# PIC32MM0256GPM048 register map
Vendor: Microchip
Registers are 32-bit, read-write, reset 0x0 unless marked. A register's access mark holds for its fields unless they carry their own. Addresses are absolute, and some are shared; only a register's first bit layout is shown; [hi:lo] are bit positions; {n}, {i} and the like mark numbered series.

## CLC1
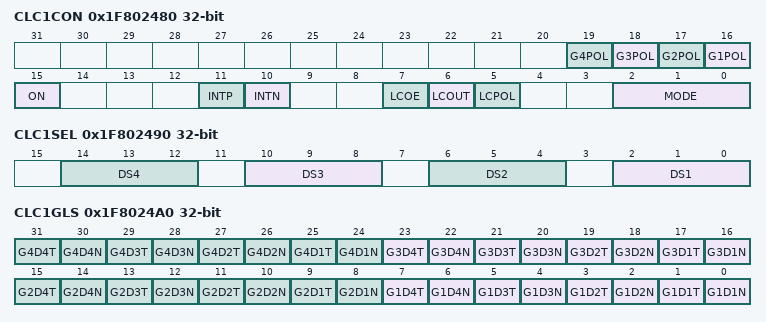
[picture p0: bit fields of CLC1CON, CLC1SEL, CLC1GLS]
0x1F802480 CLC1CON
  [n+15] G{n}POL (n=1..4), [15] ON, [11] INTP, [10] INTN, [7] LCOE, [6] LCOUT, [5] LCPOL, [2:0] MODE
0x1F802490 CLC1SEL
  [4n-2:4n-4] DS{n} (n=1..4)
0x1F8024A0 CLC1GLS
  [8n-1] G{n}D4T (n=1..4), [8n-2] G{n}D4N (n=1..4), [8n-3] G{n}D3T (n=1..4), [8n-4] G{n}D3N (n=1..4), [8n-5] G{n}D2T (n=1..4), [8n-6] G{n}D2N (n=1..4), [8n-7] G{n}D1T (n=1..4), [8n-8] G{n}D1N (n=1..4)

## CLC2
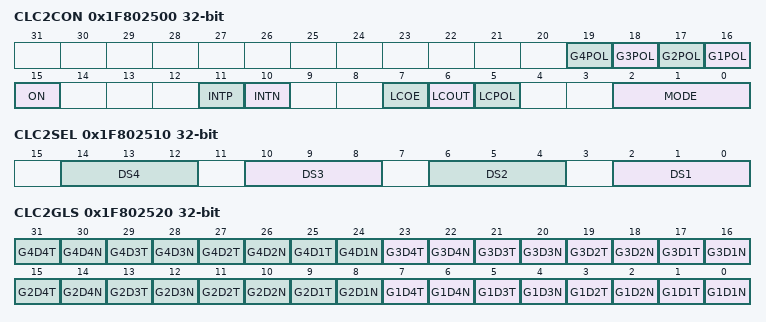
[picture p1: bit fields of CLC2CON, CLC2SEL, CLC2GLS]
0x1F802500 CLC2CON
  [n+15] G{n}POL (n=1..4), [15] ON, [11] INTP, [10] INTN, [7] LCOE, [6] LCOUT, [5] LCPOL, [2:0] MODE
0x1F802510 CLC2SEL
  [4n-2:4n-4] DS{n} (n=1..4)
0x1F802520 CLC2GLS
  [8n-1] G{n}D4T (n=1..4), [8n-2] G{n}D4N (n=1..4), [8n-3] G{n}D3T (n=1..4), [8n-4] G{n}D3N (n=1..4), [8n-5] G{n}D2T (n=1..4), [8n-6] G{n}D2N (n=1..4), [8n-7] G{n}D1T (n=1..4), [8n-8] G{n}D1N (n=1..4)

## CLC3
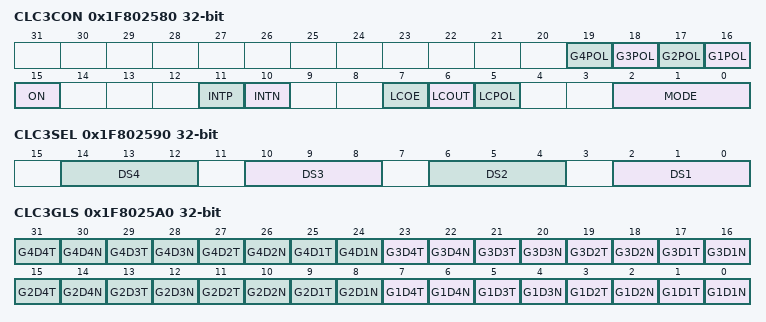
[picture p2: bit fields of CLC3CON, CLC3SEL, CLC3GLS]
0x1F802580 CLC3CON
  [n+15] G{n}POL (n=1..4), [15] ON, [11] INTP, [10] INTN, [7] LCOE, [6] LCOUT, [5] LCPOL, [2:0] MODE
0x1F802590 CLC3SEL
  [4n-2:4n-4] DS{n} (n=1..4)
0x1F8025A0 CLC3GLS
  [8n-1] G{n}D4T (n=1..4), [8n-2] G{n}D4N (n=1..4), [8n-3] G{n}D3T (n=1..4), [8n-4] G{n}D3N (n=1..4), [8n-5] G{n}D2T (n=1..4), [8n-6] G{n}D2N (n=1..4), [8n-7] G{n}D1T (n=1..4), [8n-8] G{n}D1N (n=1..4)

## CLC4
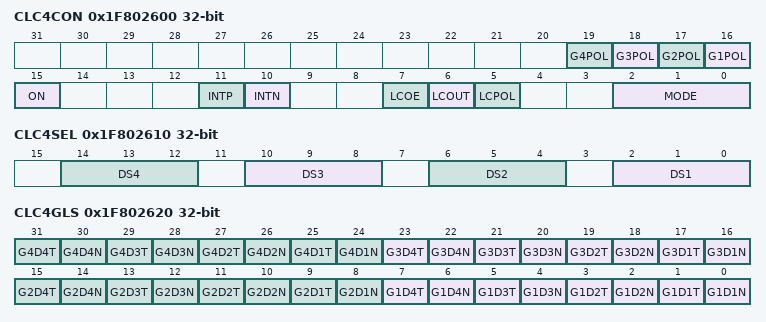
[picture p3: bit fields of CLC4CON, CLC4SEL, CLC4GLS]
0x1F802600 CLC4CON
  [n+15] G{n}POL (n=1..4), [15] ON, [11] INTP, [10] INTN, [7] LCOE, [6] LCOUT, [5] LCPOL, [2:0] MODE
0x1F802610 CLC4SEL
  [4n-2:4n-4] DS{n} (n=1..4)
0x1F802620 CLC4GLS
  [8n-1] G{n}D4T (n=1..4), [8n-2] G{n}D4N (n=1..4), [8n-3] G{n}D3T (n=1..4), [8n-4] G{n}D3N (n=1..4), [8n-5] G{n}D2T (n=1..4), [8n-6] G{n}D2N (n=1..4), [8n-7] G{n}D1T (n=1..4), [8n-8] G{n}D1N (n=1..4)

## CRU
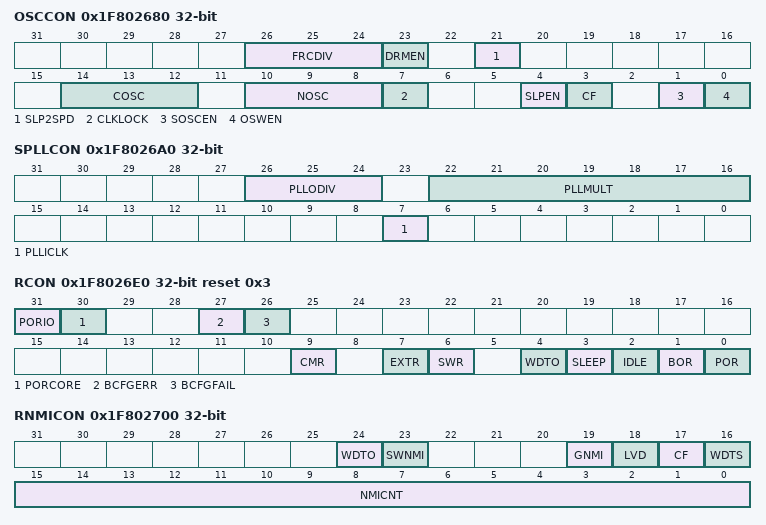
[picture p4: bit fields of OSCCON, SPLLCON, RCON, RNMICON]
0x1F802680 OSCCON reset not defined — (power-on value -----0000-x------000-xxx0--00-x0)
  [26:24] FRCDIV, [23] DRMEN, [21] SLP2SPD, [14:12] COSC ro, [10:8] NOSC, [7] CLKLOCK, [4] SLPEN, [3] CF, [1] SOSCEN, [0] OSWEN
0x1F8026A0 SPLLCON reset not defined — (power-on value -----001-xxxxxxx--------0-------)
  [26:24] PLLODIV, [22:16] PLLMULT, [7] PLLICLK
0x1F8026E0 RCON reset 0x3
  [31] PORIO, [30] PORCORE, [27] BCFGERR, [26] BCFGFAIL, [9] CMR, [7] EXTR, [6] SWR, [4] WDTO, [3] SLEEP, [2] IDLE, [1] BOR, [0] POR
0x1F8026F0 RSWRST wo
  [0] SWRST
0x1F802700 RNMICON reset not defined — (power-on value -------x0---0-000000000000000000)
  [24] WDTO, [23] SWNMI, [19] GNMI, [18] LVD, [17] CF, [16] WDTS, [15:0] NMICNT
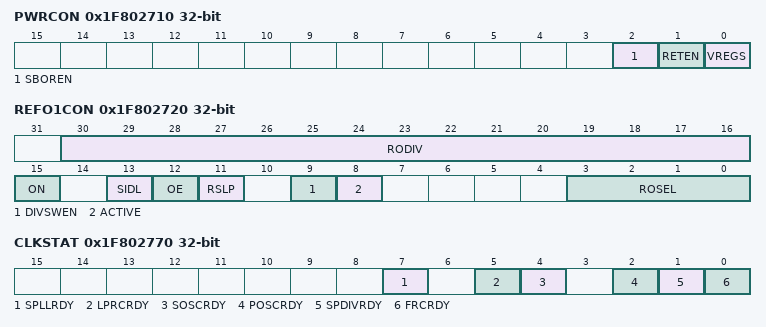
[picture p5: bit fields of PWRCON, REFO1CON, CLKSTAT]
0x1F802710 PWRCON
  [2] SBOREN, [1] RETEN, [0] VREGS
0x1F802720 REFO1CON
  [30:16] RODIV, [15] ON, [13] SIDL, [12] OE, [11] RSLP, [9] DIVSWEN, [8] ACTIVE ro, [3:0] ROSEL
0x1F802730 REFO1TRIM
  [31:23] ROTRIM
0x1F802770 CLKSTAT reset not defined — (power-on value ------------------------0-00-0x0)
  [7] SPLLRDY ro, [5] LPRCRDY ro, [4] SOSCRDY ro, [2] POSCRDY ro, [1] SPDIVRDY, [0] FRCRDY ro

## FRC
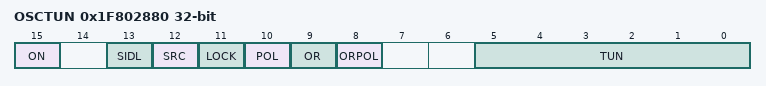
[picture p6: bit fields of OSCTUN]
0x1F802880 OSCTUN
  [15] ON, [13] SIDL, [12] SRC, [11] LOCK ro, [10] POL, [9] OR ro, [8] ORPOL, [5:0] TUN

## PORTC
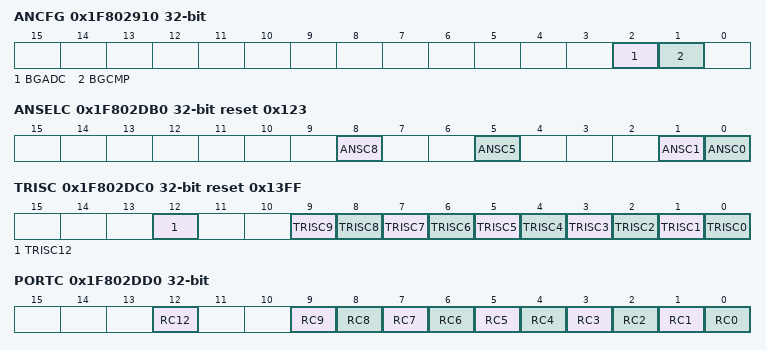
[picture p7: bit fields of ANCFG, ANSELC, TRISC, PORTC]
0x1F802910 ANCFG reset not defined — (power-on value -----------------------------xx-)
  [2] BGADC, [1] BGCMP
0x1F802DB0 ANSELC reset 0x123
  [8] ANSC8, [5] ANSC5, [1] ANSC1, [0] ANSC0
0x1F802DC0 TRISC reset 0x13FF
  [12] TRISC12, [n] TRISC{n} (n=0..9)
0x1F802DD0 PORTC reset not defined — (power-on value -------------------x--xxxxxxxxxx)
  [12] RC12, [n] RC{n} (n=0..9)
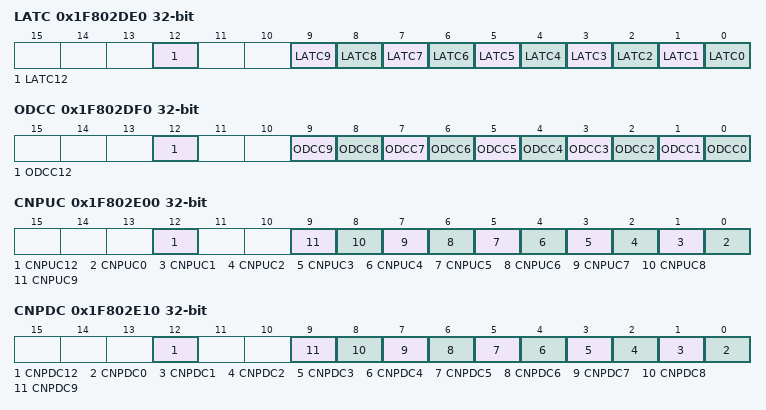
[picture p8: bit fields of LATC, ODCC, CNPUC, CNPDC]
0x1F802DE0 LATC
  [12] LATC12, [n] LATC{n} (n=0..9)
0x1F802DF0 ODCC
  [12] ODCC12, [n] ODCC{n} (n=0..9)
0x1F802E00 CNPUC
  [12] CNPUC12, [n] CNPUC{n} (n=0..9)
0x1F802E10 CNPDC
  [12] CNPDC12, [n] CNPDC{n} (n=0..9)
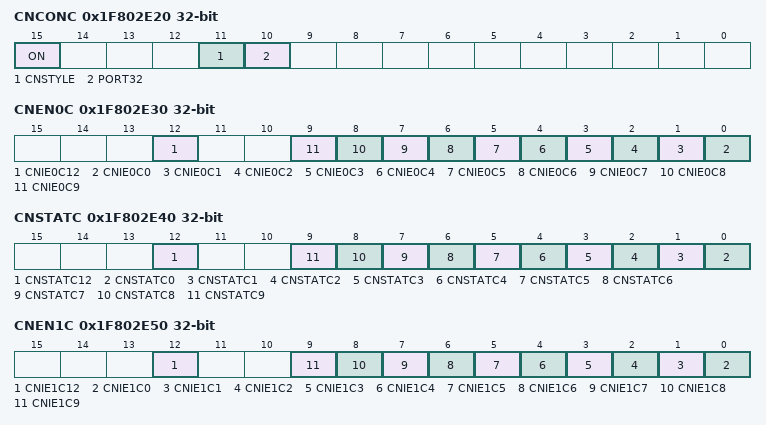
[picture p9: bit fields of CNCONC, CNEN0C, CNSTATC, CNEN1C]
0x1F802E20 CNCONC
  [15] ON, [11] CNSTYLE, [10] PORT32
0x1F802E30 CNEN0C
  [12] CNIE0C12, [n] CNIE0C{n} (n=0..9)
0x1F802E40 CNSTATC reset not defined — (power-on value -------------------x--xxxxxxxxxx)
  [12] CNSTATC12, [n] CNSTATC{n} (n=0..9)
0x1F802E50 CNEN1C
  [12] CNIE1C12, [n] CNIE1C{n} (n=0..9)
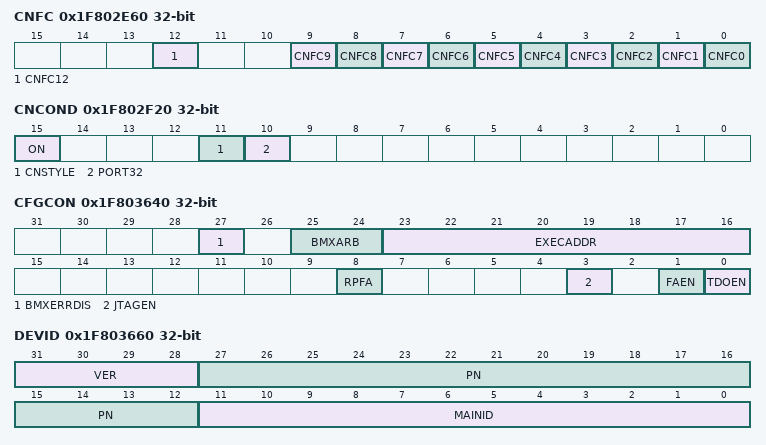
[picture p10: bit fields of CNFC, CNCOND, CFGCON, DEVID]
0x1F802E60 CNFC
  [12] CNFC12, [n] CNFC{n} (n=0..9)
0x1F802E70 SR0C access not given reset not defined
0x1F802E80 SR1C access not given reset not defined
0x1F802EB0 ANSELD access not given reset not defined
0x1F802EC0 TRISD reset 0x1
  [0] TRISD0
0x1F802ED0 PORTD reset not defined — (power-on value -------------------------------x)
  [0] RD0
0x1F802EE0 LATD
  [0] LATD0
0x1F802EF0 ODCD
  [0] ODCD0
0x1F802F00 CNPUD
  [0] CNPUD0
0x1F802F10 CNPDD
  [0] CNPDD0
0x1F802F20 CNCOND
  [15] ON, [11] CNSTYLE, [10] PORT32
0x1F802F30 CNEN0D
  [0] CNIE0D0
0x1F802F40 CNSTATD reset not defined — (power-on value -------------------------------x)
  [0] CNSTATD0
0x1F802F50 CNEN1D
  [0] CNIE1D0
0x1F802F60 CNFD
  [0] CNFD0
0x1F802F70 SR0D access not given reset not defined
0x1F802F80 SR1D access not given reset not defined
0x1F803640 CFGCON reset not defined — (power-on value ----0-0000000000-------0----x-11)
  [27] BMXERRDIS, [25:24] BMXARB, [23:16] EXECADDR, [8] RPFA, [3] JTAGEN, [1] FAEN ro, [0] TDOEN
0x1F803660 DEVID ro reset not defined — (power-on value xxxxxxxxxxxxxxxxxxxxxxxxxxxxxxxx)
  [31:28] VER, [27:12] PN, [11:0] MAINID
0x1F803670 SYSKEY
